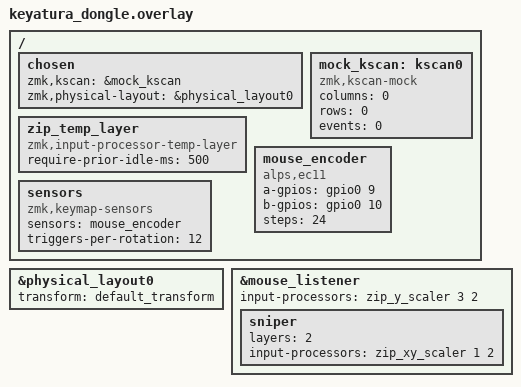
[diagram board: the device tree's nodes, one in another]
#include <input/processors.dtsi>
#include <dt-bindings/zmk/input_transform.h>
#include "keyatura-layouts.dtsi"
#include "keyatura.dtsi"
#include "keyatura_esb_addr.dtsi"


&physical_layout0 {
    transform = <&default_transform>;
};

/ {
    chosen {
        zmk,kscan = &mock_kscan;
        zmk,physical-layout = &physical_layout0;
    }; 

    mock_kscan: kscan0 {
        compatible = "zmk,kscan-mock";
        columns = <0>;
        rows = <0>;
        events = <0>;
    };

    /omit-if-no-ref/ zip_temp_layer: zip_temp_layer {
        compatible = "zmk,input-processor-temp-layer";
        #input-processor-cells = <2>;
        require-prior-idle-ms = <500>;
    };
};

&mouse_listener {
    status = "okay";
    input-processors = <&zip_y_scaler 3 2>;

    sniper {
        layers = <2>;
        input-processors = <&zip_xy_scaler 1 2>;
    };
};

/ {
	mouse_encoder: mouse_encoder {
		compatible = "alps,ec11";
        status = "okay";
		a-gpios = <&gpio0 9  (GPIO_ACTIVE_HIGH | GPIO_PULL_UP)>;
		b-gpios = <&gpio0 10 (GPIO_ACTIVE_HIGH | GPIO_PULL_UP)>;
		steps = <24>;
	};
	sensors: sensors {
		compatible = "zmk,keymap-sensors";
		status = "okay";
		sensors = <&mouse_encoder>;
		triggers-per-rotation = <12>;
	};
};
